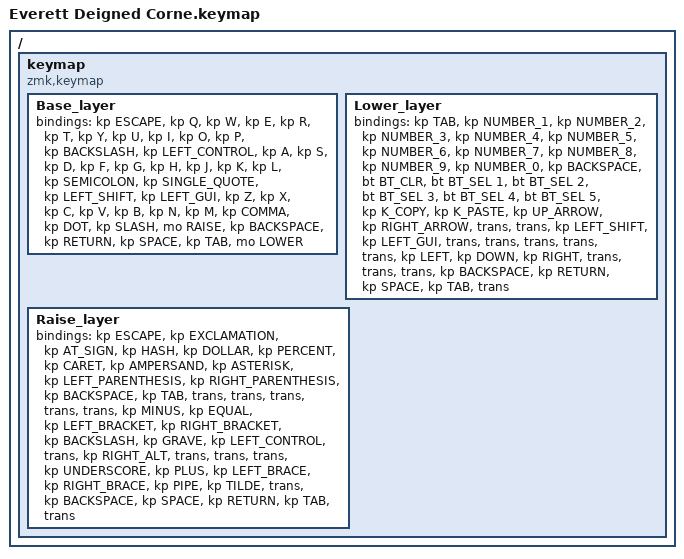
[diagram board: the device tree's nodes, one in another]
#include <behaviors.dtsi>
#include <dt-bindings/zmk/keys.h>
#include <dt-bindings/zmk/bt.h>

#define BASE 0
#define LOWER 1
#define RAISE 2

/ {
  keymap {
    compatible = "zmk,keymap";

    Base_layer {
      bindings = <
        &kp ESCAPE &kp Q &kp W &kp E &kp R &kp T &kp Y &kp U &kp I &kp O &kp P &kp BACKSLASH &kp LEFT_CONTROL &kp A &kp S &kp D &kp F &kp G &kp H &kp J &kp K &kp L &kp SEMICOLON &kp SINGLE_QUOTE &kp LEFT_SHIFT &kp LEFT_GUI &kp Z &kp X &kp C &kp V &kp B &kp N &kp M &kp COMMA &kp DOT &kp SLASH &mo RAISE &kp BACKSPACE &kp RETURN &kp SPACE &kp TAB &mo LOWER 
      >;
    };

    Lower_layer {
      bindings = <
        &kp TAB &kp NUMBER_1 &kp NUMBER_2 &kp NUMBER_3 &kp NUMBER_4 &kp NUMBER_5 &kp NUMBER_6 &kp NUMBER_7 &kp NUMBER_8 &kp NUMBER_9 &kp NUMBER_0 &kp BACKSPACE &bt BT_CLR &bt BT_SEL 1 &bt BT_SEL 2 &bt BT_SEL 3 &bt BT_SEL 4 &bt BT_SEL 5 &kp K_COPY &kp K_PASTE &kp UP_ARROW &kp RIGHT_ARROW &trans &trans &kp LEFT_SHIFT &kp LEFT_GUI &trans &trans &trans &trans &trans &kp LEFT &kp DOWN &kp RIGHT &trans &trans &trans &kp BACKSPACE &kp RETURN &kp SPACE &kp TAB &trans 
      >;
    };

    Raise_layer {
      bindings = <
        &kp ESCAPE &kp EXCLAMATION &kp AT_SIGN &kp HASH &kp DOLLAR &kp PERCENT &kp CARET &kp AMPERSAND &kp ASTERISK &kp LEFT_PARENTHESIS &kp RIGHT_PARENTHESIS &kp BACKSPACE &kp TAB &trans &trans &trans &trans &trans &kp MINUS &kp EQUAL &kp LEFT_BRACKET &kp RIGHT_BRACKET &kp BACKSLASH &kp GRAVE &kp LEFT_CONTROL &trans &kp RIGHT_ALT &trans &trans &trans &kp UNDERSCORE &kp PLUS &kp LEFT_BRACE &kp RIGHT_BRACE &kp PIPE &kp TILDE &trans &kp BACKSPACE &kp SPACE &kp RETURN &kp TAB &trans 
      >;
    };

  };
};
